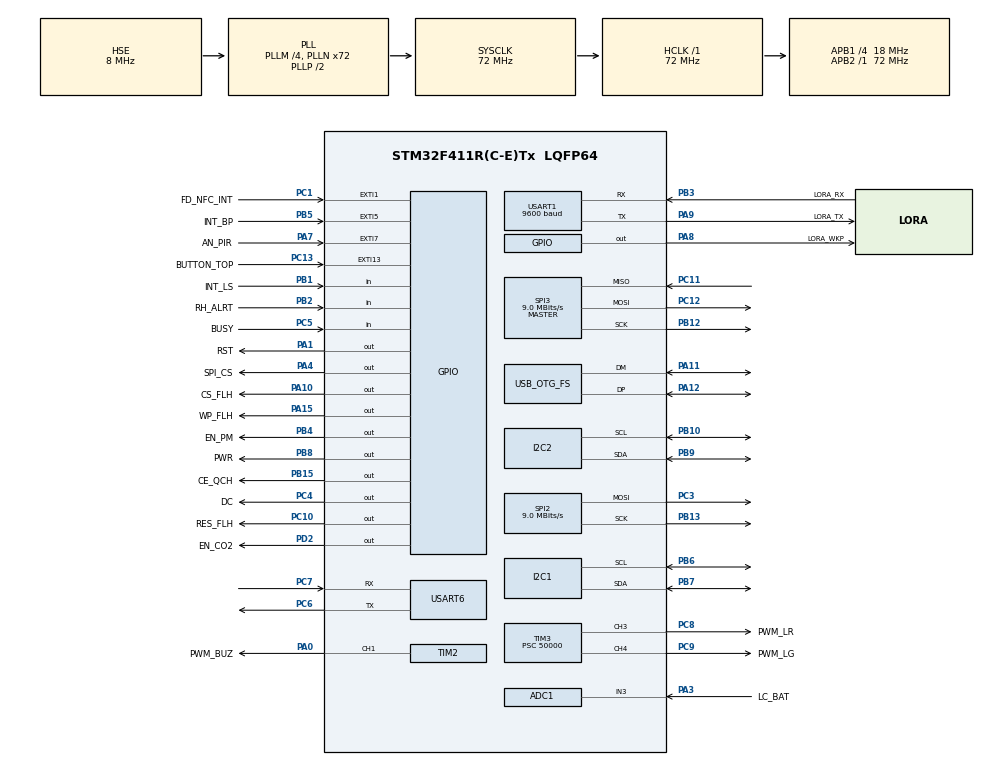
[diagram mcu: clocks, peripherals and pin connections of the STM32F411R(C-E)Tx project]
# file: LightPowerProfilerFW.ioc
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ADC1.Channel-16\#ChannelRegularConversion=ADC_CHANNEL_3
ADC1.ContinuousConvMode=ENABLE
ADC1.EOCSelection=ADC_EOC_SEQ_CONV
ADC1.NbrOfConversion=1
ADC1.NbrOfConversionFlag=1
ADC1.Rank-16\#ChannelRegularConversion=1
ADC1.SamplingTime-16\#ChannelRegularConversion=ADC_SAMPLETIME_56CYCLES
ADC1.master=1
Mcu.Family=STM32F4
Mcu.Name=STM32F411R(C-E)Tx
Mcu.Package=LQFP64
NVIC.EXTI15_10_IRQn=true\:5\:0\:true\:false\:true\:false\:true\:true\:true
NVIC.EXTI1_IRQn=true\:4\:0\:true\:false\:true\:false\:true\:true\:true
NVIC.EXTI9_5_IRQn=true\:6\:0\:true\:false\:true\:false\:true\:true\:true
NVIC.OTG_FS_IRQn=true\:0\:0\:false\:false\:true\:false\:true\:true\:true
NVIC.PriorityGroup=NVIC_PRIORITYGROUP_4
NVIC.TIM1_UP_TIM10_IRQn=true\:15\:0\:false\:false\:true\:false\:false\:true\:true
NVIC.TimeBase=TIM1_UP_TIM10_IRQn
NVIC.TimeBaseIP=TIM1
NVIC.USART1_IRQn=true\:3\:0\:true\:false\:true\:false\:true\:true\:true
PA0-WKUP.GPIO_Label=PWM_BUZ
PA0-WKUP.Signal=S_TIM2_CH1_ETR
PA1.GPIO_Label=RST
PA1.Signal=GPIO_Output
PA10.GPIO_Label=CS_FLH
PA10.GPIO_ModeDefaultOutputPP=GPIO_MODE_OUTPUT_PP
PA10.GPIO_PuPd=GPIO_PULLUP
PA10.PinState=GPIO_PIN_SET
PA10.Signal=GPIO_Output
PA11.Mode=Device_Only
PA11.Signal=USB_OTG_FS_DM
PA12.Mode=Device_Only
PA12.Signal=USB_OTG_FS_DP
PA13.Mode=Serial_Wire
PA13.Signal=SYS_JTMS-SWDIO
PA14.Mode=Serial_Wire
PA14.Signal=SYS_JTCK-SWCLK
PA15.GPIO_Label=WP_FLH
PA15.GPIO_PuPd=GPIO_PULLUP
PA15.PinState=GPIO_PIN_SET
PA15.Signal=GPIO_Output
PA3.GPIO_Label=LC_BAT
PA3.Signal=ADCx_IN3
PA4.GPIO_Label=SPI_CS
PA4.Signal=GPIO_Output
PA7.GPIO_Label=AN_PIR
PA7.GPIO_ModeDefaultEXTI=GPIO_MODE_IT_FALLING
PA7.GPIO_PuPd=GPIO_PULLUP
PA7.Signal=GPXTI7
PA8.GPIO_Label=LORA_WKP
PA8.GPIO_PuPd=GPIO_PULLUP
PA8.PinState=GPIO_PIN_SET
PA8.Signal=GPIO_Output
PA9.GPIO_Label=LORA_TX
PA9.Mode=Asynchronous
PA9.Signal=USART1_TX
PB1.GPIO_Label=INT_LS
PB1.Signal=GPIO_Input
PB10.Mode=I2C
PB10.Signal=I2C2_SCL
PB12.Mode=Full_Duplex_Master
PB12.Signal=SPI3_SCK
PB13.Mode=TX_Only_Simplex_Unidirect_Master
PB13.Signal=SPI2_SCK
PB15.GPIO_Label=CE_QCH
PB15.Signal=GPIO_Output
PB2.GPIO_Label=RH_ALRT
PB2.Signal=GPIO_Input
PB3.GPIO_Label=LORA_RX
PB3.Mode=Asynchronous
PB3.Signal=USART1_RX
PB4.GPIO_Label=EN_PM
PB4.GPIO_PuPd=GPIO_PULLDOWN
PB4.Signal=GPIO_Output
PB5.GPIO_Label=INT_BP
PB5.Signal=GPXTI5
PB6.Mode=I2C
PB6.Signal=I2C1_SCL
PB7.Mode=I2C
PB7.Signal=I2C1_SDA
PB8.GPIO_Label=PWR
PB8.GPIO_PuPd=GPIO_PULLUP
PB8.PinState=GPIO_PIN_SET
PB8.Signal=GPIO_Output
PB9.Mode=I2C
PB9.Signal=I2C2_SDA
PC1.GPIO_Label=FD_NFC_INT
PC1.GPIO_ModeDefaultEXTI=GPIO_MODE_IT_FALLING
PC1.GPIO_PuPd=GPIO_PULLUP
PC1.Signal=GPXTI1
PC10.GPIO_Label=RES_FLH
PC10.Signal=GPIO_Output
PC11.Mode=Full_Duplex_Master
PC11.Signal=SPI3_MISO
PC12.Mode=Full_Duplex_Master
PC12.Signal=SPI3_MOSI
PC13-ANTI_TAMP.GPIO_Label=BUTTON_TOP
PC13-ANTI_TAMP.Signal=GPXTI13
PC14-OSC32_IN.Mode=LSE-External-Oscillator
PC14-OSC32_IN.Signal=RCC_OSC32_IN
PC15-OSC32_OUT.Mode=LSE-External-Oscillator
PC15-OSC32_OUT.Signal=RCC_OSC32_OUT
PC3.Mode=TX_Only_Simplex_Unidirect_Master
PC3.Signal=SPI2_MOSI
PC4.GPIO_Label=DC
PC4.Signal=GPIO_Output
PC5.GPIO_Label=BUSY
PC5.GPIO_PuPd=GPIO_NOPULL
PC5.Signal=GPIO_Input
PC6.Mode=Asynchronous
PC6.Signal=USART6_TX
PC7.Mode=Asynchronous
PC7.Signal=USART6_RX
PC8.GPIO_Label=PWM_LR
PC8.Signal=S_TIM3_CH3
PC9.GPIO_Label=PWM_LG
PC9.Signal=S_TIM3_CH4
PD2.GPIO_Label=EN_CO2
PD2.GPIO_PuPd=GPIO_PULLDOWN
PD2.Signal=GPIO_Output
PH0\ -\ OSC_IN.Mode=HSE-External-Oscillator
PH0\ -\ OSC_IN.Signal=RCC_OSC_IN
PH1\ -\ OSC_OUT.Mode=HSE-External-Oscillator
PH1\ -\ OSC_OUT.Signal=RCC_OSC_OUT
ProjectManager.HeapSize=0x200
ProjectManager.StackSize=0x200
ProjectManager.TargetToolchain=CMake
RCC.48MHZClocksFreq_Value=48000000
RCC.AHBFreq_Value=72000000
RCC.APB1CLKDivider=RCC_HCLK_DIV4
RCC.APB1Freq_Value=18000000
RCC.APB1TimFreq_Value=36000000
RCC.APB2Freq_Value=72000000
RCC.APB2TimFreq_Value=72000000
RCC.CortexFreq_Value=72000000
RCC.HCLKFreq_Value=72000000
RCC.HSE_VALUE=8000000
RCC.HSI_VALUE=16000000
RCC.PLLM=4
RCC.PLLN=72
RCC.PLLQ=3
RCC.RCC_RTC_Clock_Source=RCC_RTCCLKSOURCE_LSE
RCC.RCC_RTC_Clock_SourceVirtual=RCC_RTCCLKSOURCE_LSE
RCC.SYSCLKFreq_VALUE=72000000
RCC.SYSCLKSource=RCC_SYSCLKSOURCE_PLLCLK
RCC.VCOOutputFreq_Value=144000000
SH.ADCx_IN3.0=ADC1_IN3,IN3
SH.S_TIM2_CH1_ETR.0=TIM2_CH1,PWM Generation1 CH1
SH.S_TIM3_CH3.0=TIM3_CH3,PWM Generation3 CH3
SH.S_TIM3_CH4.0=TIM3_CH4,PWM Generation4 CH4
SPI2.BaudRatePrescaler=SPI_BAUDRATEPRESCALER_2
SPI2.CalculateBaudRate=9.0 MBits/s
SPI2.Direction=SPI_DIRECTION_2LINES
SPI2.FirstBit=SPI_FIRSTBIT_MSB
SPI2.Mode=SPI_MODE_MASTER
SPI2.VirtualType=VM_MASTER
SPI3.BaudRatePrescaler=SPI_BAUDRATEPRESCALER_2
SPI3.CalculateBaudRate=9.0 MBits/s
SPI3.Direction=SPI_DIRECTION_2LINES
SPI3.Mode=SPI_MODE_MASTER
SPI3.VirtualType=VM_MASTER
STMicroelectronics.X-CUBE-AZRTOS-F4.1.1.0.AZRTOS_APP_MEM_ALLOCATION_METHOD=1
STMicroelectronics.X-CUBE-AZRTOS-F4.1.1.0.TX_DISABLE_PREEMPTION_THRESHOLD=0
STMicroelectronics.X-CUBE-AZRTOS-F4.1.1.0.TX_LOW_POWER=0
STMicroelectronics.X-CUBE-AZRTOS-F4.1.1.0.ThreadXCcRTOSJjThreadXJjCore=true
STMicroelectronics.X-CUBE-AZRTOS-F4.1.1.0.ThreadXCcRTOSJjThreadXJjLowOoPowerOosupport=true
STMicroelectronics.X-CUBE-AZRTOS-F4.1.1.0.USBD_CDCACM_EPINCMD_ADDR=1
STMicroelectronics.X-CUBE-AZRTOS-F4.1.1.0.USBD_CDCACM_EPIN_ADDR=2
STMicroelectronics.X-CUBE-AZRTOS-F4.1.1.0.USBD_CDCACM_EPOUT_ADDR=3
STMicroelectronics.X-CUBE-AZRTOS-F4.1.1.0.USBXCcUSBJjUSBXJjCoreSystem=true
STMicroelectronics.X-CUBE-AZRTOS-F4.1.1.0.USBXCcUSBJjUSBXJjUXOoDeviceOoClassOoCDCOoACM=true
STMicroelectronics.X-CUBE-AZRTOS-F4.1.1.0.USBXCcUSBJjUSBXJjUXOoDeviceOoControllers=true
STMicroelectronics.X-CUBE-AZRTOS-F4.1.1.0.USBXCcUSBJjUSBXJjUXOoDeviceOoCoreStack=true
STMicroelectronics.X-CUBE-AZRTOS-F4.1.1.0.UX_DEVICE_APP_MEM_POOL_SIZE=20*1024
STMicroelectronics.X-CUBE-AZRTOS-F4.1.1.0.UX_SLAVE_REQUEST_DATA_MAX_LENGTH=512
STMicroelectronics.X-CUBE-AZRTOS-F4.1.1.0_IsAnAzureRtosMw=true
TIM2.Channel-PWM\ Generation1\ CH1=TIM_CHANNEL_1
TIM2.Period=1000
TIM2.Prescaler=50
TIM2.Pulse-PWM\ Generation1\ CH1=568
TIM3.Channel-PWM\ Generation3\ CH3=TIM_CHANNEL_3
TIM3.Channel-PWM\ Generation4\ CH4=TIM_CHANNEL_4
TIM3.Period=6000
TIM3.Prescaler=50000
TIM3.Pulse-PWM\ Generation3\ CH3=15
TIM3.Pulse-PWM\ Generation4\ CH4=15
USART1.BaudRate=9600
USART1.VirtualMode=VM_ASYNC
USART6.VirtualMode=VM_ASYNC
USB_OTG_FS.VirtualMode=Device_Only
VP_RTC_VS_RTC_Activate.Mode=RTC_Enabled
VP_RTC_VS_RTC_Calendar.Mode=RTC_Calendar
VP_STMicroelectronics.X-CUBE-AZRTOS-F4_VS_RTOSJjThreadX_6.1.10_1.1.0.Mode=RTOSJjThreadX
VP_STMicroelectronics.X-CUBE-AZRTOS-F4_VS_USBJjUSBX_6.1.10_1.1.0.Mode=USBJjUSBX
VP_SYS_VS_tim1.Mode=TIM1
VP_TIM3_VS_ClockSourceINT.Mode=Internal
board=custom

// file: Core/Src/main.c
/* USER CODE BEGIN Header */
/**
  ******************************************************************************
  * @file           : main.c
  * @brief          : Main program body
  ******************************************************************************
  * @attention
  *
  * Copyright (c) 2024 STMicroelectronics.
  * All rights reserved.
  *
  * This software is licensed under terms that can be found in the LICENSE file
  * in the root directory of this software component.
  * If no LICENSE file comes with this software, it is provided AS-IS.
  *
  ******************************************************************************
  */
/* USER CODE END Header */
#include "app_threadx.h"
#include "main.h"
#include "adc.h"
#include "i2c.h"
#include "rtc.h"
#include "spi.h"
#include "tim.h"
#include "usart.h"
#include "gpio.h"

void SystemClock_Config(void);
/* USER CODE BEGIN PFP */

#define PUTCHAR_PROTOTYPE int __io_putchar(int ch)

/* USER CODE END PFP */

int main(void)
{

  /* MCU Configuration--------------------------------------------------------*/

  /* Reset of all peripherals, Initializes the Flash interface and the Systick. */
  HAL_Init();

  /* Configure the system clock */
  SystemClock_Config();

  /* Initialize all configured peripherals */
  MX_GPIO_Init();
  MX_I2C1_Init();
  MX_USART6_UART_Init();
  MX_SPI2_Init();
  MX_I2C2_Init();
  MX_SPI3_Init();
  MX_USART1_UART_Init();
  MX_RTC_Init();
  MX_ADC1_Init();
  MX_TIM2_Init();
  MX_TIM3_Init();

  MX_ThreadX_Init();

  /* We should never get here as control is now taken by the scheduler */

  /* Infinite loop */
  while (1)
  {

  }
}

void SystemClock_Config(void)
{
  RCC_OscInitTypeDef RCC_OscInitStruct = {0};
  RCC_ClkInitTypeDef RCC_ClkInitStruct = {0};

  /** Configure the main internal regulator output voltage
  */
  __HAL_RCC_PWR_CLK_ENABLE();
  __HAL_PWR_VOLTAGESCALING_CONFIG(PWR_REGULATOR_VOLTAGE_SCALE1);

  /** Initializes the RCC Oscillators according to the specified parameters
  * in the RCC_OscInitTypeDef structure.
  */
  RCC_OscInitStruct.OscillatorType = RCC_OSCILLATORTYPE_HSE|RCC_OSCILLATORTYPE_LSE;
  RCC_OscInitStruct.HSEState = RCC_HSE_ON;
  RCC_OscInitStruct.LSEState = RCC_LSE_ON;
  RCC_OscInitStruct.PLL.PLLState = RCC_PLL_ON;
  RCC_OscInitStruct.PLL.PLLSource = RCC_PLLSOURCE_HSE;
  RCC_OscInitStruct.PLL.PLLM = 4;
  RCC_OscInitStruct.PLL.PLLN = 72;
  RCC_OscInitStruct.PLL.PLLP = RCC_PLLP_DIV2;
  RCC_OscInitStruct.PLL.PLLQ = 3;
  if (HAL_RCC_OscConfig(&RCC_OscInitStruct) != HAL_OK)
  {
    Error_Handler();
  }

  /** Initializes the CPU, AHB and APB buses clocks
  */
  RCC_ClkInitStruct.ClockType = RCC_CLOCKTYPE_HCLK|RCC_CLOCKTYPE_SYSCLK
                              |RCC_CLOCKTYPE_PCLK1|RCC_CLOCKTYPE_PCLK2;
  RCC_ClkInitStruct.SYSCLKSource = RCC_SYSCLKSOURCE_PLLCLK;
  RCC_ClkInitStruct.AHBCLKDivider = RCC_SYSCLK_DIV1;
  RCC_ClkInitStruct.APB1CLKDivider = RCC_HCLK_DIV4;
  RCC_ClkInitStruct.APB2CLKDivider = RCC_HCLK_DIV1;

  if (HAL_RCC_ClockConfig(&RCC_ClkInitStruct, FLASH_LATENCY_2) != HAL_OK)
  {
    Error_Handler();
  }
}

/* USER CODE BEGIN 4 */

/**
 * @brief  Retargets the C library printf function to the USART.
 * @param  None
 * @retval None
 */
PUTCHAR_PROTOTYPE {
	/* Place your implementation of fputc here */
	/* e.g. write a character to the USART6 and Loop until the end of transmission */

#ifdef USE_UART6_DEBUG
	HAL_UART_Transmit(&huart6, (uint8_t*) &ch, 1, 30);
#else
	write_usb_char(*((uint8_t*)&ch));
#endif

	return ch;
}

/* USER CODE END 4 */

void HAL_TIM_PeriodElapsedCallback(TIM_HandleTypeDef *htim)
{
  if (htim->Instance == TIM1) {
    HAL_IncTick();
  }
}

void Error_Handler(void)
{
  __disable_irq();
  while (1)
  {
  }
}
